VERSION ""

NS_ :

BS_:

BU_:
VAL_TABLE_ GPS_Position_Mode 0 "None" 1 "Search" 2 "Doppler" 3 "SPS" 4 "Differential" 5 "RTK Float" 6 "RTK Integer" 7 "WAAS" 8 "OmniStar" 9 "OmniStar HP" ;
VAL_TABLE_ GPS_Velocity_Mode 0 "None" 1 "Search" 2 "Doppler" 3 "SPS" 4 "Differential" 5 "RTK Float" 6 "RTK Integer" 7 "WAAS" 8 "OmniStar" 9 "OmniStar HP" ;
VAL_TABLE_ GPS_Antenna_Mode 0 "None" 1 "Search" 2 "Doppler" 3 "SPS" 4 "Differential" 5 "RTK Float" 6 "RTK Integer" 7 "WAAS" 8 "OmniStar" 9 "OmniStar HP" ;

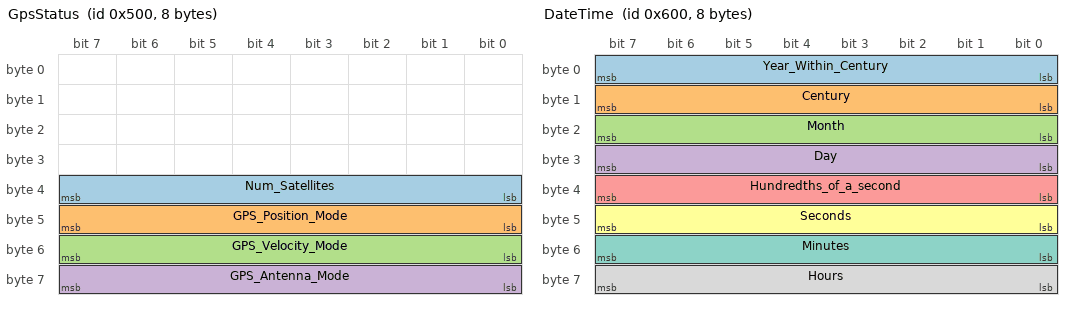
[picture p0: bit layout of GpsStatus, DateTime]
BO_ 1280 GpsStatus: 8 Vector__XXX
 SG_ Num_Satellites : 39|8@0+ (1,0) [0|255] "" Vector__XXX
 SG_ GPS_Position_Mode : 47|8@0+ (1,0) [0|9] "" Vector__XXX
 SG_ GPS_Velocity_Mode : 55|8@0+ (1,0) [0|9] "" Vector__XXX
 SG_ GPS_Antenna_Mode : 63|8@0+ (1,0) [0|9] "" Vector__XXX

BO_ 1299 DevID: 8 Vector__XXX
 SG_ ASCII_Device_ID : 7|64@0+ (1,0) [0|1] "" Vector__XXX

BO_ 1536 DateTime: 8 Vector__XXX
 SG_ Year_Within_Century : 7|8@0+ (1,0) [0|255] "Year" Vector__XXX
 SG_ Century : 15|8@0+ (100,0) [0|255] "Year" Vector__XXX
 SG_ Month : 23|8@0+ (1,0) [0|255] "Month" Vector__XXX
 SG_ Day : 31|8@0+ (1,0) [0|255] "Day" Vector__XXX
 SG_ Hundredths_of_a_second : 39|8@0+ (0.01,0) [0|255] "seconds" Vector__XXX
 SG_ Seconds : 47|8@0+ (1,0) [0|255] "Seconds" Vector__XXX
 SG_ Minutes : 55|8@0+ (1,0) [0|255] "Minutes" Vector__XXX
 SG_ Hours : 63|8@0+ (1,0) [0|255] "Hours" Vector__XXX

BO_ 1537 LatitudeLongitude: 8 Vector__XXX
 SG_ Latitude : 7|32@0- (1e-07,0) [0|4294967295] "degrees" Vector__XXX
 SG_ Longitude : 39|32@0- (1e-07,0) [0|4294967295] "degrees" Vector__XXX

BO_ 1538 Altitude: 4 Vector__XXX
 SG_ Altitude_relative_to_MSL : 7|32@0- (0.001,0) [0|4294967295] "m" Vector__XXX

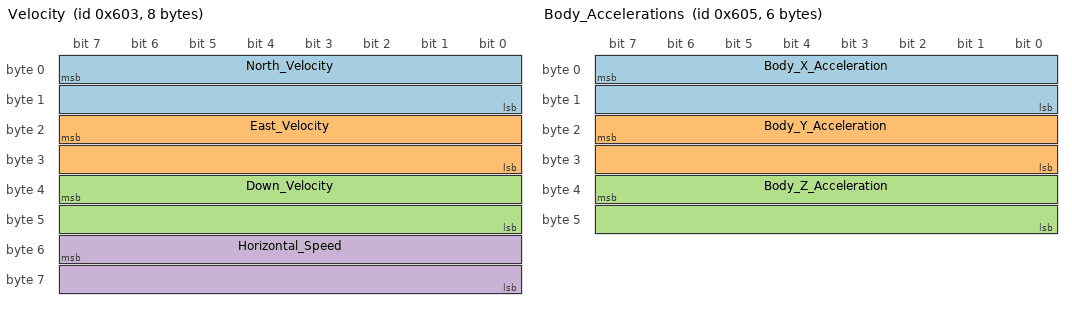
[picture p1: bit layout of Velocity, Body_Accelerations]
BO_ 1539 Velocity: 8 Vector__XXX
 SG_ North_Velocity : 7|16@0- (0.01,0) [0|65535] "m/s" Vector__XXX
 SG_ East_Velocity : 23|16@0- (0.01,0) [0|65535] "m/s" Vector__XXX
 SG_ Down_Velocity : 39|16@0- (0.01,0) [0|65535] "m/s" Vector__XXX
 SG_ Horizontal_Speed : 55|16@0+ (0.01,0) [0|65535] "m/s" Vector__XXX

BO_ 1541 Body_Accelerations: 6 Vector__XXX
 SG_ Body_X_Acceleration : 7|16@0- (0.01,0) [0|65535] "m/s^2" Vector__XXX
 SG_ Body_Y_Acceleration : 23|16@0- (0.01,0) [0|65535] "m/s^2" Vector__XXX
 SG_ Body_Z_Acceleration : 39|16@0- (0.01,0) [0|65535] "m/s^2" Vector__XXX

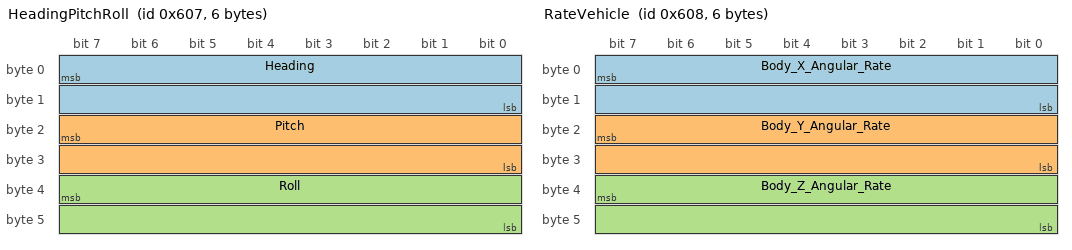
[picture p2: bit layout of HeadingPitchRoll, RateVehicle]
BO_ 1543 HeadingPitchRoll: 6 Vector__XXX
 SG_ Heading : 7|16@0+ (0.01,0) [0|65535] "degrees" Vector__XXX
 SG_ Pitch : 23|16@0- (0.01,0) [0|65535] "degrees" Vector__XXX
 SG_ Roll : 39|16@0- (0.01,0) [0|65535] "degrees" Vector__XXX

BO_ 1544 RateVehicle: 6 Vector__XXX
 SG_ Body_X_Angular_Rate : 7|16@0- (0.01,0) [0|65535] "deg/s" Vector__XXX
 SG_ Body_Y_Angular_Rate : 23|16@0- (0.01,0) [0|65535] "deg/s" Vector__XXX
 SG_ Body_Z_Angular_Rate : 39|16@0- (0.01,0) [0|65535] "deg/s" Vector__XXX

BA_DEF_ SG_  "SignalType" STRING ;
BA_DEF_DEF_  "SignalType" "";
BA_ "SignalType" SG_ 1280 GPS_Position_Mode "ENM";
BA_ "SignalType" SG_ 1280 GPS_Velocity_Mode "ENM";
BA_ "SignalType" SG_ 1280 GPS_Antenna_Mode "ENM";
BA_ "SignalType" SG_ 1299 ASCII_Device_ID "ASC";
VAL_ 1280 GPS_Position_Mode 0 "None" 1 "Search" 2 "Doppler" 3 "SPS" 4 "Differential" 5 "RTK Float" 6 "RTK Integer" 7 "WAAS" 8 "OmniStar" 9 "OmniStar HP" ;
VAL_ 1280 GPS_Velocity_Mode 0 "None" 1 "Search" 2 "Doppler" 3 "SPS" 4 "Differential" 5 "RTK Float" 6 "RTK Integer" 7 "WAAS" 8 "OmniStar" 9 "OmniStar HP" ;
VAL_ 1280 GPS_Antenna_Mode 0 "None" 1 "Search" 2 "Doppler" 3 "SPS" 4 "Differential" 5 "RTK Float" 6 "RTK Integer" 7 "WAAS" 8 "OmniStar" 9 "OmniStar HP" ;
